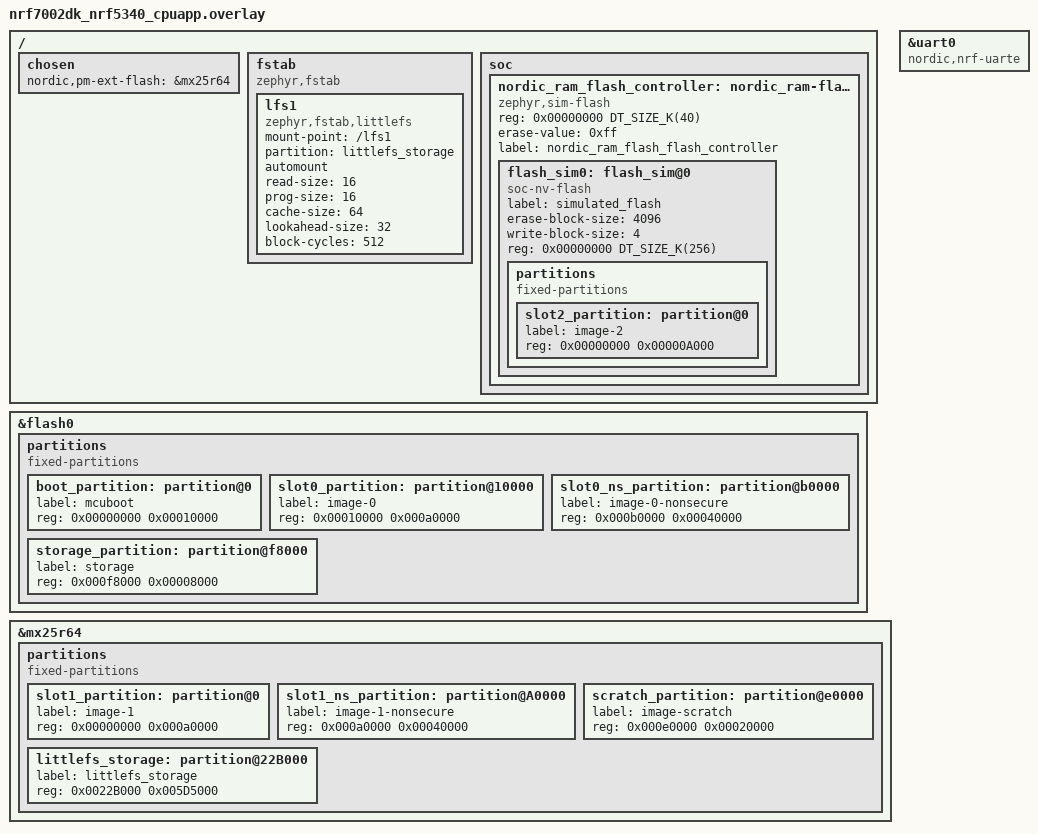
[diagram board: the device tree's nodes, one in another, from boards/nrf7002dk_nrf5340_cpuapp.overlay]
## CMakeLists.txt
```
# SPDX-License-Identifier: LicenseRef-LairdConnectivity-Clause

cmake_minimum_required(VERSION 3.20.0)

set(lcz_module_dir ${CMAKE_SOURCE_DIR}/../modules/lib/laird_connect)

# Set model number based on board
if(BOARD STREQUAL mg100)
    set(MODEL_NAME mg100)
elseif(BOARD STREQUAL pinnacle_100_dvk)
    set(MODEL_NAME p100)
elseif(BOARD STREQUAL bl5340_dvk_cpuapp)
    set(MODEL_NAME bl5340)
elseif(BOARD STREQUAL nrf7002dk_nrf5340_cpuapp)
    set(MODEL_NAME bl5340)
endif()

set(b0_DTC_OVERLAY_FILE
    ${CMAKE_SOURCE_DIR}/boards/${BOARD}.overlay
)

set(mcuboot_DTC_OVERLAY_FILE
    ${CMAKE_SOURCE_DIR}/boards/${BOARD}.overlay
)

set(b0_OVERLAY_CONFIG
    ${CMAKE_SOURCE_DIR}/config/b0.${BOARD}.conf
)

set(mcuboot_CONF_FILE
    ${CMAKE_SOURCE_DIR}/config/mcuboot.${BOARD}.conf
)

set(PM_STATIC_YML_FILE
    ${lcz_module_dir}/zephyr_lib/mcuboot_config/pm_static.sb.${BOARD}.yml
)

if((BOARD STREQUAL bl5340_dvk_cpuapp) OR(BOARD STREQUAL nrf7002dk_nrf5340_cpuapp))
    set(hci_rpmsg_OVERLAY_CONFIG ${CMAKE_SOURCE_DIR}/config/hci_rpmsg.bl5340_dvk_cpunet.conf)
endif()

if(BOARD STREQUAL nrf7002dk_nrf5340_cpuapp)
    set(WIFI_NRF_DRV_BASE ${WEST_TOPDIR}/nrf/drivers/wifi/nrf700x)
    if(CONFIG_WPA_SUPP)
        set(WPA_SUPP_BASE ${WEST_TOPDIR}/modules/lib/hostap)
    endif()
endif()

# Generate build ID based on UTC timestamp
string(TIMESTAMP build_time "%s" UTC)
set(APP_VERSION_BUILD ${build_time})
set(gen_dir ${CMAKE_BINARY_DIR}/zephyr/include/generated/app)
set(ver_file ${gen_dir}/app_version.h)
configure_file(${CMAKE_SOURCE_DIR}/src/version/app_version.h.in ${ver_file})

# Get application version
file(READ ${ver_file} ver)
string(REGEX MATCH "APP_VERSION_MAJOR ([0-9]+)" _ ${ver})
set(ver_major ${CMAKE_MATCH_1})
string(REGEX MATCH "APP_VERSION_MINOR ([0-9]+)" _ ${ver})
set(ver_minor ${CMAKE_MATCH_1})
string(REGEX MATCH "APP_VERSION_PATCH ([0-9]+)" _ ${ver})
set(ver_patch ${CMAKE_MATCH_1})
set(app_version ${ver_major}.${ver_minor}.${ver_patch}+${build_time})
message("app version: ${app_version}")

# Set application version for mcuboot
set(mcuboot_ver_conf ${CMAKE_BINARY_DIR}/generated_mcuboot_image_version.conf)
set(MCUBOOT_IMAGE_VERSION ${app_version})

# This configuration file will get automatically merged when building.
# No need to append to OVERLAY_CONFIG
configure_file(${CMAKE_SOURCE_DIR}/src/version/mcuboot_image_version.conf.in ${mcuboot_ver_conf})

# Enable firmware update
list(APPEND OVERLAY_CONFIG ${CMAKE_SOURCE_DIR}/config/firmware_update.conf)

# Enable file system
list(APPEND OVERLAY_CONFIG ${CMAKE_SOURCE_DIR}/config/filesystem.conf)

# MBED TLS for secure IoT
list(APPEND OVERLAY_CONFIG ${CMAKE_SOURCE_DIR}/config/mbedtls.conf)

# Enable hardware unique key generation
list(APPEND OVERLAY_CONFIG ${CMAKE_SOURCE_DIR}/config/hardware_key.conf)

# Enable networking support
list(APPEND OVERLAY_CONFIG ${CMAKE_SOURCE_DIR}/config/networking.conf)

# Enable BLE
list(APPEND OVERLAY_CONFIG ${CMAKE_SOURCE_DIR}/config/ble.conf)

# Enable device management
list(APPEND OVERLAY_CONFIG ${CMAKE_SOURCE_DIR}/config/device_management.conf)

# Enable memfault
list(APPEND OVERLAY_CONFIG ${CMAKE_SOURCE_DIR}/config/memfault.conf)
set(MEMFAULT_SW_VER ${ver_major}.${ver_minor}.${ver_patch})
set(MEMFAULT_HW_VER ${BOARD})
set(memfault_info_conf ${CMAKE_BINARY_DIR}/generated_memfault_info.conf)

# This configuration file will get automatically merged when building.
# No need to append to OVERLAY_CONFIG
configure_file(${CMAKE_SOURCE_DIR}/src/version/memfault_info.conf.in ${memfault_info_conf})

# Enable Laird Connectivity BLE sensor scanning
list(APPEND OVERLAY_CONFIG ${CMAKE_SOURCE_DIR}/config/ble_sensors.conf)

# WiFi configuration
if(BOARD STREQUAL nrf7002dk_nrf5340_cpuapp)
    list(APPEND OVERLAY_CONFIG ${CMAKE_SOURCE_DIR}/config/wifi.conf)
endif()

# App configuration
if(APP_TYPE STREQUAL lwm2m)
    list(APPEND OVERLAY_CONFIG ${CMAKE_SOURCE_DIR}/config/lwm2m_telemetry.conf)
    message("Device Management with LwM2M Telemetry")
elseif(APP_TYPE STREQUAL mqtt)
    list(APPEND OVERLAY_CONFIG ${CMAKE_SOURCE_DIR}/config/mqtt_telemetry.conf)
    message("Device Management with MQTT Telemetry")
elseif(APP_TYPE STREQUAL none)
    message("Device Management without Telemetry")
else()
    message(FATAL_ERROR "Unknown app type ${APP_TYPE}")
endif()
set(API_KEYS ${MODEL_NAME}+${APP_TYPE})
set(API_NAME ${MODEL_NAME}_${APP_TYPE})
set(ATTR_CUSTOM_PATH_BASE ${CMAKE_SOURCE_DIR}/components/attributes/${API_NAME})

# Add framework ID and msgcode files prior to Zephyr package init
set(FWK_APP_ID_FILE_LIST ${CMAKE_SOURCE_DIR}/src/framework_config/fwk_ids.h)
set(FWK_APP_MSG_FILE_LIST ${CMAKE_SOURCE_DIR}/src/framework_config/fwk_msg_codes.h)

find_package(Zephyr REQUIRED HINTS $ENV{ZEPHYR_BASE})
project(ble_gateway_dm_firmware)

# Build the API
execute_process(
    COMMAND
    ${PYTHON_EXECUTABLE}
    ${CMAKE_SOURCE_DIR}/../modules/lib/laird_connect/attributes/generator/api.py
    ${CMAKE_SOURCE_DIR}
    ${API_KEYS}
    WORKING_DIRECTORY ${CMAKE_SOURCE_DIR}
    RESULT_VARIABLE api_result
)

if(NOT "${api_result}" STREQUAL 0)
    message(FATAL_ERROR "Failed to build API")
endif()

# Include Memfault configs
if(CONFIG_LCZ_MEMFAULT)
    if((BOARD STREQUAL mg100) OR(BOARD STREQUAL pinnacle_100_dvk))
        zephyr_include_directories(${CMAKE_SOURCE_DIR}/memfault/mg100)
    elseif((BOARD STREQUAL bl5340_dvk_cpuapp) OR(BOARD STREQUAL nrf7002dk_nrf5340_cpuapp))
        zephyr_include_directories(${CMAKE_SOURCE_DIR}/memfault/bl5340)
    endif()
endif()

zephyr_include_directories(${CMAKE_SOURCE_DIR}/config/include)

target_include_directories(app PRIVATE ${gen_dir})

target_sources(app PRIVATE src/main.c)
```

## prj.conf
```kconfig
CONFIG_NEWLIB_LIBC=y
CONFIG_HEAP_MEM_POOL_SIZE=16384
CONFIG_BOOT_BANNER=n

CONFIG_THREAD_RUNTIME_STATS=y

CONFIG_LCZ=y
CONFIG_LCZ_SOFTWARE_RESET=y
CONFIG_FRAMEWORK=y
CONFIG_BUFFER_POOL_SIZE=576
CONFIG_BUFFER_POOL_SHELL=y
CONFIG_FWK_ASSERT_ENABLED=y
CONFIG_FWK_AUTO_GENERATE_FILES=y
CONFIG_SYSTEM_MESSAGE_TASK=y


# Logging system
CONFIG_LOG=y
CONFIG_LOG_BUFFER_SIZE=2048
CONFIG_LOG_TIMESTAMP_64BIT=y
CONFIG_LOG_BACKEND_FS=y
CONFIG_LOG_BACKEND_FS_DIR="/lfs1/logs"
CONFIG_LOG_BACKEND_FS_FILE_SIZE=128000
CONFIG_LOG_BACKEND_FS_FILES_LIMIT=8

# Command shell
CONFIG_SHELL=y
CONFIG_SHELL_HISTORY=n
CONFIG_SHELL_STACK_SIZE=3072
CONFIG_SHELL_THREAD_PRIORITY_OVERRIDE=y
# Change priority to be higher than logging thread to avoid log messages not showing at boot
CONFIG_SHELL_THREAD_PRIORITY=13
CONFIG_DEVMEM_SHELL=n
CONFIG_LCZ_SHELL_LOGIN=y
CONFIG_SHELL_LOGIN_INIT_PRIORITY=75
CONFIG_SHELL_LOGIN_INIT_USING_ATTRIBUTES=y
CONFIG_SHELL_PROMPT_UART="login: "
CONFIG_SHELL_CMD_ROOT="login"
CONFIG_LCZ_SHELL_SCRIPT_RUNNER=y
CONFIG_SHELL_BACKEND_DUMMY=y
CONFIG_THREAD_MAX_NAME_LEN=16

# MCUMGR
CONFIG_MCUMGR=y
CONFIG_LCZ_MCUMGR_WRAPPER=y
CONFIG_MCUMGR_SMP_SHELL=y
CONFIG_MCUBOOT_SHELL_ERASE_ENABLED=n
CONFIG_MCUMGR_CMD_SHELL_MGMT=y
CONFIG_MCUMGR_CMD_OS_MGMT=y
CONFIG_OS_MGMT_MCUMGR_PARAMS=y
CONFIG_SYSTEM_WORKQUEUE_STACK_SIZE=4864

# Attributes
CONFIG_LCZ_KVP=y
CONFIG_LCZ_KVP_LOG_LEVEL_DBG=y
CONFIG_ATTR=y
CONFIG_ATTR_BROADCAST=y
CONFIG_ATTR_ENCRYPTED=y
CONFIG_ATTR_FILE_NAME="enc/attr.txt"
CONFIG_ATTR_ID_CONDITIONAL_CODE_ENABLE=y
CONFIG_ATTR_SHELL=y
CONFIG_MCUMGR_CMD_ATTRIBUTE_MGMT=y

# Init before app
CONFIG_LCZ_PARAM_FILE=y
CONFIG_LCZ_PARAM_FILE_ENCRYPTED=y
CONFIG_LCZ_PARAM_FILE_MOUNT_POINT="/lfs1"
CONFIG_LCZ_PARAM_FILE_INIT_PRIORITY=60

# PKI authentication and management
CONFIG_LCZ_PKI_AUTH=y
CONFIG_LCZ_PKI_AUTH_SMP_CENTRAL=y
CONFIG_LCZ_PKI_AUTH_SMP_PERIPHERAL=y

CONFIG_FPU=y
```

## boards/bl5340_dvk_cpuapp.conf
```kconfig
CONFIG_BOOTLOADER_MCUBOOT=y
CONFIG_SECURE_BOOT=y
CONFIG_BUILD_S1_VARIANT=y

CONFIG_FLASH_SIMULATOR=n

# Turn on Bluetooth to ensure building an image for network core
CONFIG_BT=y

# Networking
CONFIG_SPI=y
CONFIG_NET_L2_ETHERNET=y
CONFIG_ETH_ENC424J600=y
CONFIG_NET_DHCPV4=y

# LEDs
CONFIG_LCZ_NUMBER_OF_LEDS=4
```

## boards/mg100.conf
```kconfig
CONFIG_BOOTLOADER_MCUBOOT=y
CONFIG_SECURE_BOOT=y
CONFIG_BUILD_S1_VARIANT=y

CONFIG_NRF_APPROTECT_LOCK=y
CONFIG_LCZ_APPROTECT=y
# Uncomment for readback protection.
# CONFIG_LCZ_APPROTECT_STARTUP=y
# Needs to be after HUK generation
# CONFIG_LCZ_APPROTECT_STARTUP_INIT_LEVEL=3
# CONFIG_LCZ_APPROTECT_STARTUP_INIT_PRIORITY=2

# Networking
CONFIG_MODEM=y
CONFIG_MODEM_HL7800_BOOT_DELAY=y
CONFIG_MODEM_HL7800_RX_WORKQ_STACK_SIZE=1400
CONFIG_MODEM_LOG_LEVEL_DBG=y
CONFIG_MODEM_HL7800_CONFIGURE_BANDS=n
CONFIG_MODEM_HL7800_ADDRESS_FAMILY_IPV4=y

#CONFIG_PM_DEVICE=y
#CONFIG_MODEM_HL7800_LOW_POWER_MODE=y
#CONFIG_MODEM_HL7800_PSM=y
#CONFIG_MODEM_HL7800_PSM_ACTIVE_TIME="00001010"
#CONFIG_MODEM_HL7800_PSM_PERIODIC_TAU="00111000"
#CONFIG_MODEM_HL7800_ALLOW_SLEEP_DELAY_MS=1000
#CONFIG_MODEM_HL7800_SLEEP_LEVEL_SLEEP=y
CONFIG_LCZ_MODEM_HL7800=y
CONFIG_MODEM_HL7800=y
# LwM2M
# The latency in NB-IoT can be 10 seconds.
# these values need to be greater than 10 seconds to account for the
# the latency of the connection after the cell tower.
CONFIG_NET_SOCKETS_CONNECT_TIMEOUT=13000
CONFIG_NET_SOCKETS_DTLS_TIMEOUT=15000
CONFIG_COAP_INIT_ACK_TIMEOUT_MS=15000
CONFIG_LWM2M_SECONDS_TO_UPDATE_EARLY=20

# Device Management
CONFIG_LCZ_LWM2M_SW_MGMT_HL7800=y
CONFIG_MODEM_HL7800_FW_UPDATE=y
CONFIG_SMT_QUEUE_SIZE=16

# LEDs
CONFIG_LCZ_NUMBER_OF_LEDS=3

# BLE
CONFIG_BT_CTLR_TX_PWR_PLUS_8=y
CONFIG_BT_CTLR_PHY_CODED=y
CONFIG_BT_CTLR_DATA_LENGTH_MAX=251

# Power management
CONFIG_LOCKING=y
CONFIG_LCZ_POWER=y
CONFIG_LCZ_ADC_START_SAMPLE_AFTER_INIT=n
CONFIG_LCZ_POWER_INIT_PRIORITY=99
```

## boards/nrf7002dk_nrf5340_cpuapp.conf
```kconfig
CONFIG_BOOTLOADER_MCUBOOT=y
CONFIG_SECURE_BOOT=y
CONFIG_BUILD_S1_VARIANT=y

CONFIG_FLASH_SIMULATOR=n
CONFIG_PM_OVERRIDE_EXTERNAL_DRIVER_CHECK=y

# Turn on Bluetooth to ensure building an image for network core
CONFIG_BT=y

# Networking
CONFIG_SPI=y
CONFIG_NET_L2_ETHERNET=y
CONFIG_NET_DHCPV4=y

# LEDs
CONFIG_LCZ_NUMBER_OF_LEDS=2
```

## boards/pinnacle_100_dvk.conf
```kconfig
CONFIG_BOOTLOADER_MCUBOOT=y
CONFIG_SECURE_BOOT=y
CONFIG_BUILD_S1_VARIANT=y

CONFIG_NRF_APPROTECT_LOCK=y
CONFIG_LCZ_APPROTECT=y
# Uncomment for readback protection.
# CONFIG_LCZ_APPROTECT_STARTUP=y
# Needs to be after HUK generation
# CONFIG_LCZ_APPROTECT_STARTUP_INIT_LEVEL=3
# CONFIG_LCZ_APPROTECT_STARTUP_INIT_PRIORITY=2

# Networking
CONFIG_MODEM=y
CONFIG_MODEM_HL7800_BOOT_DELAY=y
CONFIG_MODEM_HL7800_RX_WORKQ_STACK_SIZE=1400
CONFIG_MODEM_LOG_LEVEL_DBG=y
CONFIG_MODEM_HL7800_CONFIGURE_BANDS=n
CONFIG_MODEM_HL7800_ADDRESS_FAMILY_IPV4=y
# CONFIG_PM_DEVICE=y
# CONFIG_MODEM_HL7800_LOW_POWER_MODE=y
# CONFIG_MODEM_HL7800_ALLOW_SLEEP_DELAY_MS=1000
# CONFIG_MODEM_HL7800_SLEEP_LEVEL_SLEEP=y
CONFIG_LCZ_MODEM_HL7800=y

# LwM2M
# The latency in NB-IoT can be 10 seconds.
# these values need to be greater than 10 seconds to account for the
# the latency of the connection after the cell tower.
CONFIG_NET_SOCKETS_CONNECT_TIMEOUT=13000
CONFIG_NET_SOCKETS_DTLS_TIMEOUT=15000
CONFIG_COAP_INIT_ACK_TIMEOUT_MS=15000
CONFIG_LWM2M_SECONDS_TO_UPDATE_EARLY=20

# Device Management
CONFIG_LCZ_LWM2M_SW_MGMT_HL7800=y
CONFIG_MODEM_HL7800_FW_UPDATE=y

# LEDs
CONFIG_LCZ_NUMBER_OF_LEDS=4

# BLE
CONFIG_BT_CTLR_TX_PWR_PLUS_8=y
CONFIG_BT_CTLR_PHY_CODED=y
CONFIG_BT_CTLR_DATA_LENGTH_MAX=251

# Power management
CONFIG_LOCKING=y
CONFIG_LCZ_POWER=y
CONFIG_LCZ_POWER_INIT_PRIORITY=99
```

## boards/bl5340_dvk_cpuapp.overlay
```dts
/*
 * Copyright (c) 2021 Nordic Semiconductor ASA
 * Copyright (c) 2022 Laird Connectivity LLC
 *
 * SPDX-License-Identifier: LicenseRef-Nordic-5-Clause
 */

 /delete-node/ &lfs_partition;

/ {
	chosen {
		nordic,pm-ext-flash = &mx25r64;
	};

	fstab {
		compatible = "zephyr,fstab";
		lfs1: lfs1 {
			compatible = "zephyr,fstab,littlefs";
			mount-point = "/lfs1";
			partition = <&littlefs_storage>;
			automount;
			read-size = <16>;
			prog-size = <16>;
			cache-size = <64>;
			lookahead-size = <32>;
			block-cycles = <512>;
		};
	};

	aliases {
		mcuboot-button0 = &boot_button0;
		mcuboot-led0 = &led4;
	};
};

&mx25r64 {
	partitions {
		compatible = "fixed-partitions";
		#address-cells = <1>;
		#size-cells = <1>;

		littlefs_storage: partition@22B000 {
			label = "littlefs_storage";
			reg = <0x0022B000 0x005D5000>;
		};
	};
};

/*
 * This section is used to enable a partition which is used through the flash API
 * but which is in reality stored in RAM. This is done to load data from
 * external flash to the network core. Since the network core cannot access
 * the external flash directly, the data is buffered in RAM before being
 * copied by the network core to the network core flash.
 *
 * The partition must be enabled by the application configuration to prevent
 * bus faults when mcumgr tries to access simulated partition with network core
 * image data.
 */

/ {
	soc {
		/* Add a flash controller which has the compatible
		 * 'zephyr,sim-flash'. This will ensure that the flash
		 * simulator can use it. None of the other properties in this
		 * node is used for anything.
		 */
		nordic_ram_flash_controller: nordic_ram-flash-controller@0 {
			compatible = "zephyr,sim-flash";
			reg = <0x00000000 DT_SIZE_K(40)>;
			#address-cells = <1>;
			#size-cells = <1>;
			erase-value = <0xff>;
			label = "nordic_ram_flash_flash_controller";

			/* This node label must match that used in the flash
			 * simulator.
			 */
			flash_sim0: flash_sim@0 {
				status = "okay";
				compatible = "soc-nv-flash";
				label = "simulated_flash";
				erase-block-size = <4096>;
				write-block-size = <4>;
				reg = <0x00000000 DT_SIZE_K(256)>;

				partitions {
					compatible = "fixed-partitions";
					#address-cells = <1>;
					#size-cells = <1>;

					/* This partition must be defined for
					 * MCUboot to find the partition ID
					 * of the primary slot for image 1,
					 * which is stored in this partition.
					 */
					slot2_partition: partition@0 {
						label = "image-2";
						reg = <0x00000000 0x00000A000>;
					};
				};
			};
		};
	};
};

&uart0 {
	compatible = "nordic,nrf-uarte";
};
```

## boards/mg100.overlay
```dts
/delete-node/ &lfs_partition;

/ {
	chosen {
		/* required for partition manager to use external flash */
		nordic,pm-ext-flash = &mx25r64;
	};

	fstab {
		compatible = "zephyr,fstab";
		lfs1: lfs1 {
			compatible = "zephyr,fstab,littlefs";
			mount-point = "/lfs1";
			partition = <&littlefs_storage>;
			automount;
			read-size = <16>;
			prog-size = <16>;
			cache-size = <64>;
			lookahead-size = <32>;
			block-cycles = <512>;
		};
	};

	aliases {
		mcuboot-button0 = &button1;
		mcuboot-led0 = &led2;
	};
};

&mx25r64 {
	partitions {
		compatible = "fixed-partitions";
		#address-cells = <1>;
		#size-cells = <1>;

		littlefs_storage: partition@200000 {
			label = "littlefs_storage";
			reg = <0x00200000 0x00600000>;
		};
	};
};

&uart0 {
	compatible = "nordic,nrf-uarte";
};
```

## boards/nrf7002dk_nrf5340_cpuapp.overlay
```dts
/*
 * Copyright (c) 2021 Nordic Semiconductor ASA
 * Copyright (c) 2022 Laird Connectivity LLC
 *
 * SPDX-License-Identifier: LicenseRef-Nordic-5-Clause
 */

/delete-node/ &boot_partition;
/delete-node/ &slot0_partition;
/delete-node/ &slot0_ns_partition;
/delete-node/ &slot1_partition;
/delete-node/ &slot1_ns_partition;
/delete-node/ &scratch_partition;
/delete-node/ &storage_partition;

/ {
	chosen {
		nordic,pm-ext-flash = &mx25r64;
	};

	fstab {
		compatible = "zephyr,fstab";
		lfs1: lfs1 {
			compatible = "zephyr,fstab,littlefs";
			mount-point = "/lfs1";
			partition = <&littlefs_storage>;
			automount;
			read-size = <16>;
			prog-size = <16>;
			cache-size = <64>;
			lookahead-size = <32>;
			block-cycles = <512>;
		};
	};
};

&flash0 {
	partitions {
		compatible = "fixed-partitions";
		#address-cells = <1>;
		#size-cells = <1>;

		/* 64K */
		boot_partition: partition@0 {
			label = "mcuboot";
			reg = <0x00000000 0x00010000>;
		};
		/* 640K */
		slot0_partition: partition@10000 {
			label = "image-0";
			reg = <0x00010000 0x000a0000>;
		};
		/* 256K */
		slot0_ns_partition: partition@b0000 {
			label = "image-0-nonsecure";
			reg = <0x000b0000 0x00040000>;
		};

		/*
		 * The flash starting at 0x000f8000 and ending at
		 * 0x000fffff is reserved for use by the application.
		 */

		/*
		 * Storage partition will be used by FCB/NVS
		 * if enabled. 32K
		 */
		storage_partition: partition@f8000 {
			label = "storage";
			reg = <0x000f8000 0x00008000>;
		};
	};
};

&mx25r64 {
	partitions {
		compatible = "fixed-partitions";
		#address-cells = <1>;
		#size-cells = <1>;

		/* 640K */
		slot1_partition: partition@0 {
			label = "image-1";
			reg = <0x00000000 0x000a0000>;
		};
		/* 256K */
		slot1_ns_partition: partition@A0000 {
			label = "image-1-nonsecure";
			reg = <0x000a0000 0x00040000>;
		};
		/* 128K */
		scratch_partition: partition@e0000 {
			label = "image-scratch";
			reg = <0x000e0000 0x00020000>;
		};

		littlefs_storage: partition@22B000 {
			label = "littlefs_storage";
			reg = <0x0022B000 0x005D5000>;
		};
	};
};

/*
 * This section is used to enable a partition which is used through the flash API
 * but which is in reality stored in RAM. This is done to load data from
 * external flash to the network core. Since the network core cannot access
 * the external flash directly, the data is buffered in RAM before being
 * copied by the network core to the network core flash.
 *
 * The partition must be enabled by the application configuration to prevent
 * bus faults when mcumgr tries to access simulated partition with network core
 * image data.
 */

/ {
	soc {
		/* Add a flash controller which has the compatible
		 * 'zephyr,sim-flash'. This will ensure that the flash
		 * simulator can use it. None of the other properties in this
		 * node is used for anything.
		 */
		nordic_ram_flash_controller: nordic_ram-flash-controller@0 {
			compatible = "zephyr,sim-flash";
			reg = <0x00000000 DT_SIZE_K(40)>;
			#address-cells = <1>;
			#size-cells = <1>;
			erase-value = <0xff>;
			label = "nordic_ram_flash_flash_controller";

			/* This node label must match that used in the flash
			 * simulator.
			 */
			flash_sim0: flash_sim@0 {
				status = "okay";
				compatible = "soc-nv-flash";
				label = "simulated_flash";
				erase-block-size = <4096>;
				write-block-size = <4>;
				reg = <0x00000000 DT_SIZE_K(256)>;

				partitions {
					compatible = "fixed-partitions";
					#address-cells = <1>;
					#size-cells = <1>;

					/* This partition must be defined for
					 * MCUboot to find the partition ID
					 * of the primary slot for image 1,
					 * which is stored in this partition.
					 */
					slot2_partition: partition@0 {
						label = "image-2";
						reg = <0x00000000 0x00000A000>;
					};
				};
			};
		};
	};
};

&uart0 {
	compatible = "nordic,nrf-uarte";
};
```

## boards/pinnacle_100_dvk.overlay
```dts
/delete-node/ &lfs_partition;

/ {
	chosen {
		/* required for partition manager to use external flash */
		nordic,pm-ext-flash = &mx25r64;
	};

	fstab {
		compatible = "zephyr,fstab";
		lfs1: lfs1 {
			compatible = "zephyr,fstab,littlefs";
			mount-point = "/lfs1";
			partition = <&littlefs_storage>;
			automount;
			read-size = <16>;
			prog-size = <16>;
			cache-size = <64>;
			lookahead-size = <32>;
			block-cycles = <512>;
		};
	};
};

&mx25r64 {
	partitions {
		compatible = "fixed-partitions";
		#address-cells = <1>;
		#size-cells = <1>;

		littlefs_storage: partition@200000 {
			label = "littlefs_storage";
			reg = <0x00200000 0x00600000>;
		};
	};
};

&uart0 {
	compatible = "nordic,nrf-uarte";
};
```

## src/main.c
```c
/*
 * Copyright (c) 2022 Laird Connectivity LLC
 *
 * SPDX-License-Identifier: LicenseRef-LairdConnectivity-Clause
 */

/**************************************************************************************************/
/* Includes                                                                                       */
/**************************************************************************************************/
#include <zephyr/logging/log.h>
LOG_MODULE_REGISTER(main, LOG_LEVEL_DBG);
#include <zephyr/zephyr.h>
#include <version.h>
#ifdef CONFIG_LCZ_HW_KEY
#include <lcz_hw_key.h>
#endif
#ifdef CONFIG_ATTR
#include <attr.h>
#endif
#ifdef CONFIG_LCZ_LWM2M_CLIENT
#include <lcz_lwm2m_client.h>
#endif
#ifdef CONFIG_LCZ_LWM2M_FW_UPDATE
#include <lcz_lwm2m_fw_update.h>
#endif
#include "app_version.h"
#ifdef CONFIG_SHELL_BACKEND_SERIAL
#include <zephyr/shell/shell_uart.h>
#endif
#include <zephyr/drivers/uart.h>

/**************************************************************************************************/
/* Local Constant, Macro and Type Definitions                                                     */
/**************************************************************************************************/
#define PKG_NAME CONFIG_MEMFAULT_NCS_FW_TYPE "-" CONFIG_BOARD "-"

#define DEFAULT_BAUD_RATE 115200

static struct uart_config uart_cfg = {
	.baudrate = DEFAULT_BAUD_RATE,
	.parity = UART_CFG_PARITY_NONE,
	.stop_bits = UART_CFG_STOP_BITS_1,
	.data_bits = UART_CFG_DATA_BITS_8,
	.flow_ctrl = UART_CFG_FLOW_CTRL_RTS_CTS,
};

/**************************************************************************************************/
/* Global Function Definitions                                                                    */
/**************************************************************************************************/
void main(void)
{
	const struct device *uart_dev;
	int ret;

#ifdef CONFIG_SHELL_BACKEND_SERIAL
	/* Disable log output by default on the UART console.
	 * Re-enable logging using the 'log go' cmd.
	 * LCZ_SHELL_LOGIN selects SHELL_START_OBSCURED which disables log output before main().
	 */
#ifdef CONFIG_ATTR
	if (attr_get_bool(ATTR_ID_log_on_boot) == false)
#endif
	{
		log_backend_deactivate(shell_backend_uart_get_ptr()->log_backend->backend);
	}
#endif

#ifdef CONFIG_ATTR
	if (attr_get_bool(ATTR_ID_disable_flow_control)) {
		uart_cfg.flow_ctrl = UART_CFG_FLOW_CTRL_NONE;
	}
	uart_cfg.baudrate = attr_get_uint32(ATTR_ID_baud_rate, DEFAULT_BAUD_RATE);
#endif

	uart_dev = DEVICE_DT_GET(DT_CHOSEN(zephyr_console));
	if (device_is_ready(uart_dev)) {
		ret = uart_configure(uart_dev, &uart_cfg);
		if (ret != 0) {
			LOG_ERR("Could not config console UART [%d]", ret);
		}
	} else {
		LOG_ERR("Console UART not ready");
	}

#ifdef CONFIG_ATTR
	(void)attr_set_string(ATTR_ID_firmware_version, APP_VERSION_STRING,
			      strlen(APP_VERSION_STRING));
	(void)attr_set_string(ATTR_ID_board, CONFIG_BOARD, strlen(CONFIG_BOARD));
#endif
#ifdef CONFIG_LCZ_LWM2M_CLIENT
	(void)lcz_lwm2m_client_set_device_firmware_version(APP_VERSION_STRING);
	(void)lcz_lwm2m_client_set_software_version(KERNEL_VERSION_STRING);
#endif
#ifdef CONFIG_LCZ_LWM2M_FW_UPDATE
	(void)lcz_lwm2m_fw_update_set_pkg_name(PKG_NAME);
#endif

	LOG_INF("BLE Gateway DM Firmware v%s [%s]", APP_VERSION_STRING, CONFIG_BOARD);
}
```
